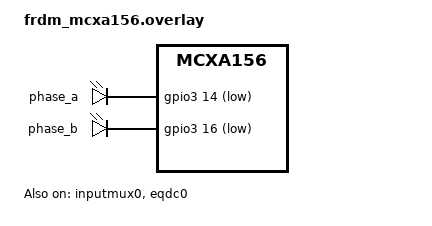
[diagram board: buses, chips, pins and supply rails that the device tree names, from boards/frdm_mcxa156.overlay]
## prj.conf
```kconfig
CONFIG_SENSOR=y
CONFIG_PRINTK=y
CONFIG_GPIO=y
CONFIG_EQDC_MCUX=y
```

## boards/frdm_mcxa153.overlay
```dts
/*
 * SPDX-FileCopyrightText: 2026 NXP
 *
 * SPDX-License-Identifier: Apache-2.0
 */

/ {
	aliases {
		qdec0 = &eqdc0;
		qenca = &phase_a;
		qencb = &phase_b;
	};

	encoder-emulate {
		compatible = "gpio-leds";

		phase_a: phase_a {
			gpios = <&gpio3 12 GPIO_ACTIVE_LOW>;
		};

		phase_b: phase_b {
			gpios = <&gpio3 13 GPIO_ACTIVE_LOW>;
		};
	};
};

/* J1-12 ---> J4-1 (EQDC PHASEA)
 * J1-14 ---> J4-3 (EQDC PHASEB)
 */
&pinctrl {
	eqdc_pinmux: eqdc_pinmux {
		group0 {
			pinmux = <TRIG_IN5_P2_7>;
			drive-strength = "high";
			slew-rate = "fast";
			input-enable;
		};

		group1 {
			pinmux = <TRIG_IN10_P3_31>;
			drive-strength = "high";
			slew-rate = "fast";
			input-enable;
		};
	};
};

&inputmux0 {
	status = "okay";
};

&eqdc0 {
	status = "okay";
	pinctrl-0 = <&eqdc_pinmux>;
	pinctrl-names = "default";
	counts-per-revolution = <120>;
	revolution-count-mode = <1>;
	prescaler = <15>;
	input-filter-period = <1>;
	inputmux-connections = <&inputmux0 0 0x37000022>,
			       <&inputmux0 0 0x36c0001d>;
};
```

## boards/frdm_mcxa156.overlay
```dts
/*
 * SPDX-FileCopyrightText: 2026 NXP
 *
 * SPDX-License-Identifier: Apache-2.0
 */

/ {
	aliases {
		qdec0 = &eqdc0;
		qenca = &phase_a;
		qencb = &phase_b;
	};

	encoder-emulate {
		compatible = "gpio-leds";

		phase_a: phase_a {
			gpios = <&gpio3 14 GPIO_ACTIVE_LOW>;
		};

		phase_b: phase_b {
			gpios = <&gpio3 16 GPIO_ACTIVE_LOW>;
		};
	};
};

&inputmux0 {
	status = "okay";
};

&eqdc0 {
	status = "okay";
	counts-per-revolution = <120>;
};
```

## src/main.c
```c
/*
 * Copyright (c) 2022 Valerio Setti <valerio.setti@gmail.com>
 *
 * SPDX-License-Identifier: Apache-2.0
 */

#include <zephyr/kernel.h>
#include <zephyr/device.h>
#include <zephyr/drivers/sensor.h>
#include <zephyr/sys/printk.h>

#define QUAD_ENC_EMUL_ENABLED \
	DT_NODE_EXISTS(DT_ALIAS(qenca)) && DT_NODE_EXISTS(DT_ALIAS(qencb))

#if QUAD_ENC_EMUL_ENABLED

#include <zephyr/drivers/gpio.h>

#define QUAD_ENC_EMUL_PERIOD 100

static const struct gpio_dt_spec phase_a =
			GPIO_DT_SPEC_GET(DT_ALIAS(qenca), gpios);
static const struct gpio_dt_spec phase_b =
			GPIO_DT_SPEC_GET(DT_ALIAS(qencb), gpios);
static bool toggle_a;

void qenc_emulate_work_handler(struct k_work *work)
{
	toggle_a = !toggle_a;
	if (toggle_a) {
		gpio_pin_toggle_dt(&phase_a);
	} else {
		gpio_pin_toggle_dt(&phase_b);
	}
}

static K_WORK_DEFINE(qenc_emulate_work, qenc_emulate_work_handler);

static void qenc_emulate_timer_handler(struct k_timer *dummy)
{
	k_work_submit(&qenc_emulate_work);
}

static K_TIMER_DEFINE(qenc_emulate_timer, qenc_emulate_timer_handler, NULL);

static void qenc_emulate_init(void)
{
	printk("Quadrature encoder emulator enabled with %u ms period\n",
		QUAD_ENC_EMUL_PERIOD);

	if (!gpio_is_ready_dt(&phase_a)) {
		printk("%s: device not ready.", phase_a.port->name);
		return;
	}
	gpio_pin_configure_dt(&phase_a, GPIO_OUTPUT);

	if (!gpio_is_ready_dt(&phase_b)) {
		printk("%s: device not ready.", phase_b.port->name);
		return;
	}
	gpio_pin_configure_dt(&phase_b, GPIO_OUTPUT);

	k_timer_start(&qenc_emulate_timer, K_MSEC(QUAD_ENC_EMUL_PERIOD / 2),
			K_MSEC(QUAD_ENC_EMUL_PERIOD / 2));
}

#else

static void qenc_emulate_init(void) { };

#endif /* QUAD_ENC_EMUL_ENABLED */

int main(void)
{
	struct sensor_value val;
	int rc;
	const struct device *const dev = DEVICE_DT_GET(DT_ALIAS(qdec0));

	if (!device_is_ready(dev)) {
		printk("Qdec device is not ready\n");
		return 0;
	}

	printk("Quadrature decoder sensor test\n");

	qenc_emulate_init();

#ifndef CONFIG_COVERAGE
	while (true) {
#else
	for (int i = 0; i < 3; i++) {
#endif
		/* sleep first to gather position from first period */
		k_msleep(1000);

		rc = sensor_sample_fetch(dev);
		if (rc != 0) {
			printk("Failed to fetch sample (%d)\n", rc);
			return 0;
		}

		rc = sensor_channel_get(dev, SENSOR_CHAN_ROTATION, &val);
		if (rc != 0) {
			printk("Failed to get data (%d)\n", rc);
			return 0;
		}

		printk("Position = %d degrees\n", val.val1);


		/* Get speed (optional)*/
		rc = sensor_channel_get(dev, SENSOR_CHAN_RPM, &val);
		if (rc == 0) {
			printk("Speed = %d RPM\n", val.val1);
		}

		/* Get revolutions (optional)*/
		rc = sensor_channel_get(dev, SENSOR_CHAN_ENCODER_REVOLUTIONS, &val);
		if (rc == 0) {
			printk("Revolutions = %d\n", val.val1);
		}
	}
	return 0;
}
```
